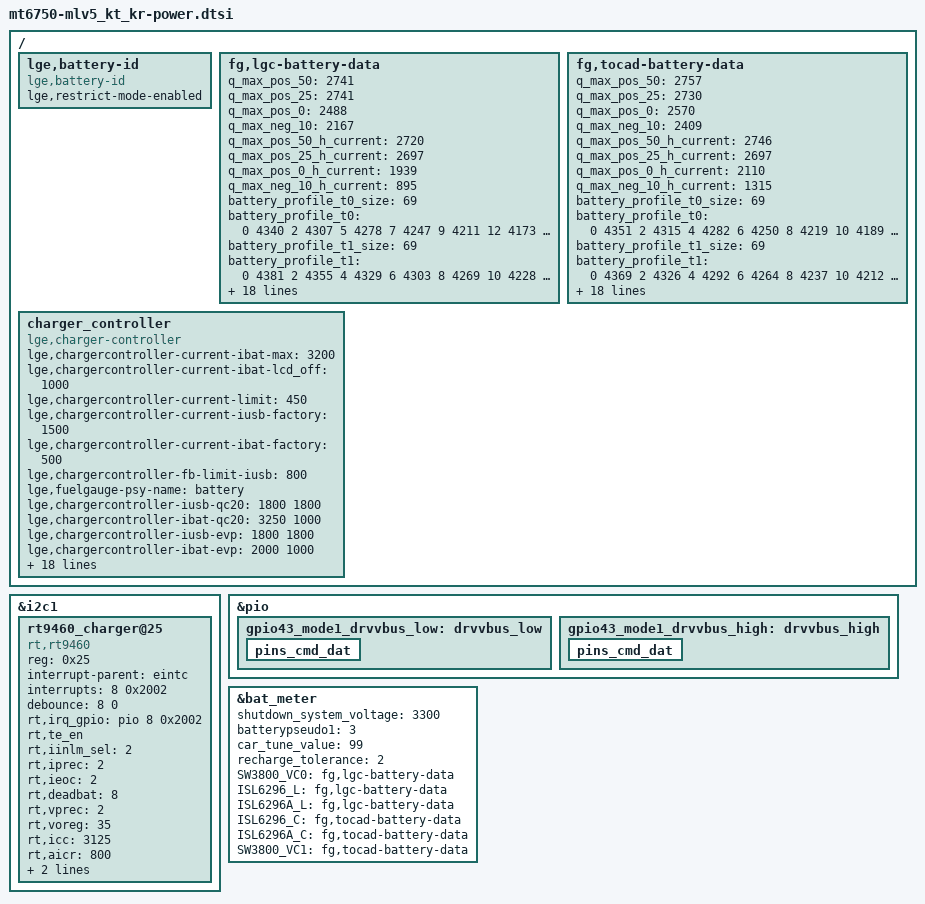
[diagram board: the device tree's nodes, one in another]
/*
 * LG Electronics LV5 power device tree source
 *
 * Copyright (c) 2016 LG Electronics Co., Ltd.
 *              http://www.lge.com
 *
 */

&i2c1 {
	rt9460_charger@25 {
		status = "okay";
		compatible = "rt,rt9460";
		reg = <0x25>;
		interrupt-parent = <&eintc>;
		interrupts = <8 0x2002>;
		debounce = <8 0>;
		rt,irq_gpio = <&pio 8 0x2002>;
		rt,te_en;
		rt,iinlm_sel = <2>;
		rt,iprec = <2>;
		rt,ieoc = <2>;
		rt,deadbat = <8>;
		rt,vprec = <2>;
		rt,voreg = <35>;
		rt,icc = <3125>;
		rt,aicr = <800>;
		rt,chg_volt = <4400>;
		rt,bst_volt = <5000>;
	};
};
/ {
	lge,battery-id{
		compatible = "lge,battery-id";
		lge,restrict-mode-enabled;
	};
};

&pio {
	gpio43_mode1_drvvbus_low: drvvbus_low{
		pins_cmd_dat {
			/delete-property/ pins;
			/delete-property/ slew-rate;
			/delete-property/ output-low;
		};
	};
	gpio43_mode1_drvvbus_high: drvvbus_high{
		pins_cmd_dat {
			/delete-property/ pins;
			/delete-property/ slew-rate;
			/delete-property/ output-high;
		};
	};
};

/* battery_profile */
&bat_meter {
	shutdown_system_voltage = <3300>;
	batterypseudo1 = <3 >;
	car_tune_value = <99 >;
	recharge_tolerance = <2>;
	/* battery id */ /*need to check for LGC 2nd battery and TOCAD battery ID*/
	SW3800_VC0 = "fg,lgc-battery-data";
	ISL6296_L = "fg,lgc-battery-data";
	ISL6296A_L = "fg,lgc-battery-data";
	ISL6296_C = "fg,tocad-battery-data";
	ISL6296A_C = "fg,tocad-battery-data";
	SW3800_VC1 = "fg,tocad-battery-data";
};

/{
	/* LGC 2800mA Battery 3.4V cut off */
	fg,lgc-battery-data {
		/* Qmax for 0mA */
		q_max_pos_50 = <2741 >;
		q_max_pos_25 = <2741 >;
		q_max_pos_0 = <2488 >;
		q_max_neg_10 = <2167 >;
		/* Qmax for 400mA, said high current */
		q_max_pos_50_h_current = <2720 >;
		q_max_pos_25_h_current = <2697 >;
		q_max_pos_0_h_current = <1939 >;
		q_max_neg_10_h_current = <895 >;

		battery_profile_t0_size = <69 >;
		battery_profile_t0 = <
			0 4340 	2 4307 	5 4278 	7 4247 	9 4211
			12 4173 	14 4143 	16 4118 	18 4097 	21 4076
			23 4051 	25 4024 	28 3997 	30 3974 	32 3953
			35 3935 	37 3919 	39 3903 	42 3887 	44 3873
			46 3862 	48 3850 	51 3839 	53 3829 	55 3820
			58 3811 	60 3803 	62 3795 	65 3789 	67 3782
			69 3776 	72 3768 	74 3760 	76 3752 	78 3743
			81 3733 	83 3723 	85 3713 	88 3701 	90 3688
			92 3671 	95 3643 	97 3589 	99 3473 	100 3353
			100 3272 	100 3219 	100 3175 	100 3136 	100 3101
			100 3078 	100 3061 	100 3045 	100 3027 	100 3007
			100 2997 	100 3001 	100 2999 	100 2995 	100 2992
			100 2989 	100 2515 	100 2517 	100 2520 	100 2515
			100 2521 	100 2519 	100 2520 	100 2520
			>;
		battery_profile_t1_size = <69 >;
		battery_profile_t1 = <
			0 4381 	2 4355 	4 4329 	6 4303 	8 4269
			10 4228 	12 4190 	14 4163 	16 4140 	18 4119
			20 4099 	22 4082 	24 4061 	26 4039 	28 4017
			30 3997 	32 3980 	34 3963 	36 3946 	38 3928
			40 3909 	42 3891 	44 3874 	46 3860 	48 3848
			50 3838 	52 3829 	54 3820 	56 3812 	58 3804
			60 3798 	62 3791 	64 3788 	66 3783 	68 3778
			70 3774 	72 3769 	74 3763 	76 3757 	78 3748
			80 3739 	82 3729 	84 3718 	86 3706 	88 3696
			90 3686 	92 3676 	94 3660 	96 3617 	98 3522
			100 3430 	100 3388 	100 3359 	100 3337 	100 3319
			100 3304 	100 3292 	100 3281 	100 3270 	100 3261
			100 3252 	100 3244 	100 3237 	100 3230 	100 3223
			100 3217 	100 3210 	100 3204 	100 3204
			>;
		battery_profile_t2_size = <69 >;
		battery_profile_t2 = <
			0 4389 	2 4356 	4 4329 	5 4304 	7 4280
			9 4258 	11 4236 	13 4214 	15 4193 	16 4171
			18 4151 	20 4131 	22 4111 	24 4092 	25 4074
			27 4057 	29 4038 	31 4018 	33 4001 	35 3986
			36 3972 	38 3959 	40 3944 	42 3929 	44 3914
			45 3894 	47 3875 	49 3859 	51 3847 	53 3836
			55 3828 	56 3819 	58 3813 	60 3805 	62 3799
			64 3794 	65 3788 	67 3783 	69 3779 	71 3775
			73 3771 	74 3766 	76 3761 	78 3752 	80 3744
			82 3737 	84 3727 	85 3714 	87 3700 	89 3685
			91 3680 	93 3676 	94 3669 	96 3639 	98 3552
			100 3411 	100 3104 	100 3035 	100 2997 	100 2971
			100 2956 	100 2947 	100 2941 	100 2934 	100 2929
			100 2927 	100 2926 	100 2921 	100 2921
			>;
		battery_profile_t3_size = <69 >;
		battery_profile_t3 = <
			0 4394 	2 4358 	4 4329 	5 4304 	7 4279
			9 4256 	11 4233 	13 4212 	15 4189 	16 4169
			18 4148 	20 4127 	22 4107 	24 4088 	25 4069
			27 4051 	29 4033 	31 4016 	33 3999 	35 3984
			36 3968 	38 3954 	40 3940 	42 3927 	44 3913
			45 3896 	47 3874 	49 3856 	51 3844 	53 3834
			55 3825 	56 3817 	58 3809 	60 3802 	62 3796
			64 3789 	65 3784 	67 3779 	69 3775 	71 3770
			73 3763 	74 3750 	76 3743 	78 3736 	80 3729
			82 3722 	84 3713 	85 3700 	87 3687 	89 3671
			91 3666 	93 3662 	94 3654 	96 3624 	98 3542
			100 3411 	100 3141 	100 2970 	100 2926 	100 2903
			100 2890 	100 2880 	100 2875 	100 2869 	100 2865
			100 2863 	100 2862 	100 2857 	100 2857
			>;
		r_profile_t0_size = <69 >;
		r_profile_t0 = <
			795 4340 	795 4307 	830 4278 	853 4247 	908 4211
			1018 4173 	1108 4143 	1145 4118 	1163 4097 	1210 4076
			1228 4051 	1223 4024 	1213 3997 	1208 3974 	1208 3953
			1205 3935 	1213 3919 	1215 3903 	1223 3887 	1228 3873
			1245 3862 	1250 3850 	1263 3839 	1268 3829 	1278 3820
			1283 3811 	1308 3803 	1320 3795 	1325 3789 	1360 3782
			1380 3776 	1415 3768 	1438 3760 	1458 3752 	1488 3743
			1528 3733 	1575 3723 	1613 3713 	1673 3701 	1740 3688
			1788 3671 	1835 3643 	1880 3589 	1493 3473 	1383 3353
			1183 3272 	1053 3219 	940 3175 	845 3136 	765 3101
			703 3078 	655 3061 	615 3045 	590 3027 	543 3007
			520 2997 	563 3001 	558 2999 	1350 2995 	978 2992
			1365 2989 	180 2515 	185 2517 	193 2520 	180 2515
			195 2521 	190 2519 	193 2520 	193 2520
			>;
		r_profile_t1_size = <69 >;
		r_profile_t1 = <
			345 4381 	345 4355 	353 4329 	363 4303 	378 4269
			423 4228 	513 4190 	568 4163 	585 4140 	590 4119
			595 4099 	620 4082 	643 4061 	648 4039 	645 4017
			643 3997 	648 3980 	653 3963 	653 3946 	658 3928
			653 3909 	653 3891 	650 3874 	648 3860 	655 3848
			663 3838 	673 3829 	678 3820 	688 3812 	695 3804
			705 3798 	715 3791 	730 3788 	743 3783 	768 3778
			785 3774 	805 3769 	828 3763 	855 3757 	880 3748
			913 3739 	948 3729 	988 3718 	1028 3706 	1078 3696
			1140 3686 	1218 3676 	1308 3660 	1398 3617 	1498 3522
			1578 3430 	1470 3388 	1400 3359 	1350 3337 	1303 3319
			1265 3304 	1233 3292 	1218 3281 	1183 3270 	1155 3261
			1138 3252 	1123 3244 	1095 3237 	1098 3230 	1070 3223
			1068 3217 	1055 3210 	1040 3204 	1020 3204
			>;
		r_profile_t2_size = <69 >;
		r_profile_t2 = <
			145 4389 	145 4356 	143 4329 	143 4304 	140 4280
			143 4258 	145 4236 	143 4214 	148 4193 	145 4171
			145 4151 	150 4131 	153 4111 	155 4092 	160 4074
			163 4057 	168 4038 	168 4018 	173 4001 	175 3986
			178 3972 	185 3959 	185 3944 	188 3929 	185 3914
			170 3894 	160 3875 	148 3859 	145 3847 	145 3836
			148 3828 	145 3819 	150 3813 	150 3805 	155 3799
			158 3794 	158 3788 	160 3783 	163 3779 	163 3775
			165 3771 	163 3766 	165 3761 	160 3752 	165 3744
			173 3737 	178 3727 	183 3714 	188 3700 	188 3685
			203 3680 	223 3676 	255 3669 	278 3639 	313 3552
			403 3411 	765 3104 	603 3035 	508 2997 	435 2971
			398 2956 	380 2947 	358 2941 	358 2934 	330 2929
			320 2927 	318 2926 	318 2921 	323 2921
			>;
		r_profile_t3_size = <69 >;
		r_profile_t3 = <
			98 4394 	98 4358 	98 4329 	98 4304 	95 4279
			95 4256 	95 4233 	98 4212 	95 4189 	100 4169
			100 4148 	100 4127 	100 4107 	103 4088 	105 4069
			108 4051 	108 4033 	110 4016 	110 3999 	115 3984
			115 3968 	120 3954 	123 3940 	128 3927 	130 3913
			128 3896 	113 3874 	103 3856 	100 3844 	100 3834
			100 3825 	103 3817 	103 3809 	105 3802 	108 3796
			110 3789 	113 3784 	115 3779 	118 3775 	120 3770
			115 3763 	103 3750 	105 3743 	105 3736 	108 3729
			110 3722 	110 3713 	110 3700 	110 3687 	108 3671
			113 3666 	120 3662 	128 3654 	125 3624 	140 3542
			163 3411 	280 3141 	425 2970 	315 2926 	270 2903
			235 2890 	213 2880 	198 2875 	183 2869 	170 2865
			165 2863 	160 2862 	160 2857 	145 2857
			>;
	};
	/* TOCAD 2800mA Battery 3.4V cut off */  /*temporary using lgc battery data*/
	fg,tocad-battery-data {
		/* Qmax for 0mA */
		q_max_pos_50 = <2757 >;
		q_max_pos_25 = <2730 >;
		q_max_pos_0 = <2570 >;
		q_max_neg_10 = <2409 >;
		/* Qmax for 400mA, said high current */
		q_max_pos_50_h_current = <2746 >;
		q_max_pos_25_h_current = <2697 >;
		q_max_pos_0_h_current = <2110 >;
		q_max_neg_10_h_current = <1315 >;

		battery_profile_t0_size = <69 >;
		battery_profile_t0 = <
			0 4351 	2 4315 	4 4282 	6 4250 	8 4219
			10 4189 	12 4162 	14 4138 	17 4113 	19 4090
			21 4068 	23 4047 	25 4026 	27 4004 	29 3985
			31 3967 	33 3948 	35 3930 	37 3910 	39 3891
			41 3874 	44 3858 	46 3845 	48 3833 	50 3822
			52 3813 	54 3807 	56 3801 	58 3797 	60 3792
			62 3789 	64 3785 	66 3782 	68 3778 	70 3773
			72 3769 	75 3762 	77 3755 	79 3746 	81 3734
			83 3723 	85 3711 	87 3700 	89 3691 	91 3682
			93 3673 	95 3659 	96 3649 	97 3645 	97 3640
			98 3636 	98 3633 	98 3629 	98 3625 	99 3621
			99 3616 	99 3612 	99 3608 	99 3603 	99 3599
			99 3594 	99 3590 	100 3585 	100 3581 	100 3577
			100 3573 	100 3569 	100 3564 	100 3400
			>;
		battery_profile_t1_size = <69 >;
		battery_profile_t1 = <
			0 4369 	2 4326 	4 4292 	6 4264 	8 4237
			10 4212 	12 4187 	14 4164 	16 4140 	17 4118
			19 4097 	21 4078 	23 4058 	25 4039 	27 4019
			29 4001 	31 3985 	33 3968 	35 3952 	37 3934
			39 3915 	41 3897 	43 3879 	45 3864 	47 3849
			49 3839 	50 3830 	52 3820 	54 3812 	56 3805
			58 3798 	60 3793 	62 3788 	64 3785 	66 3783
			68 3779 	70 3776 	72 3773 	74 3769 	76 3763
			78 3755 	80 3745 	81 3734 	83 3721 	85 3704
			87 3692 	89 3683 	91 3675 	93 3667 	95 3653
			97 3610 	98 3587 	98 3568 	98 3551 	99 3537
			99 3524 	99 3513 	99 3503 	99 3492 	99 3483
			99 3475 	100 3466 	100 3459 	100 3451 	100 3443
			100 3436 	100 3429 	100 3423 	100 3400
			>;
		battery_profile_t2_size = <69 >;
		battery_profile_t2 = <
			0 4386 	2 4357 	4 4335 	5 4314 	7 4292
			9 4271 	11 4250 	13 4228 	15 4207 	16 4186
			18 4165 	20 4144 	22 4124 	24 4104 	26 4085
			27 4067 	29 4048 	31 4030 	33 4014 	35 3997
			37 3982 	38 3968 	40 3953 	42 3936 	44 3917
			46 3896 	48 3878 	49 3864 	51 3852 	53 3842
			55 3833 	57 3825 	58 3817 	60 3811 	62 3804
			64 3798 	66 3793 	68 3788 	69 3783 	71 3779
			73 3775 	75 3770 	77 3765 	79 3758 	80 3750
			82 3742 	84 3729 	86 3716 	88 3697 	90 3688
			91 3686 	93 3683 	95 3678 	97 3642 	99 3538
			100 3348 	100 3141 	100 3064 	100 3030 	100 3010
			100 2997 	100 2989 	100 2979 	100 2972 	100 2965
			100 2960 	100 2957 	100 2952 	100 2952
			>;
		battery_profile_t3_size = <69 >;
		battery_profile_t3 = <
			0 4395 	2 4369 	4 4347 	5 4327 	7 4306
			9 4284 	11 4263 	13 4242 	14 4221 	16 4198
			18 4177 	20 4157 	22 4136 	24 4116 	25 4097
			27 4077 	29 4059 	31 4041 	33 4024 	34 4008
			36 3992 	38 3976 	40 3962 	42 3948 	43 3934
			45 3916 	47 3893 	49 3875 	51 3862 	52 3851
			54 3840 	56 3832 	58 3823 	60 3816 	62 3808
			63 3802 	65 3797 	67 3791 	69 3786 	71 3782
			72 3775 	74 3765 	76 3757 	78 3749 	80 3742
			81 3733 	83 3726 	85 3712 	87 3698 	89 3680
			90 3677 	92 3675 	94 3673 	96 3663 	98 3595
			99 3470 	100 3214 	100 3085 	100 3045 	100 3021
			100 3002 	100 2985 	100 2974 	100 2963 	100 2954
			100 2946 	100 2939 	100 2931 	100 2931
			>;
		r_profile_t0_size = <69 >;
		r_profile_t0 = <
			693 4351 	693 4315 	723 4282 	743 4250 	763 4219
			785 4189 	808 4162 	835 4138 	855 4113 	875 4090
			898 4068 	918 4047 	935 4026 	948 4004 	968 3985
			985 3967 	1000 3948 	1013 3930 	1015 3910 	1013 3891
			1008 3874 	1000 3858 	998 3845 	995 3833 	998 3822
			998 3813 	1010 3807 	1018 3801 	1030 3797 	1045 3792
			1068 3789 	1093 3785 	1123 3782 	1153 3778 	1183 3773
			1218 3769 	1245 3762 	1278 3755 	1315 3746 	1353 3734
			1400 3723 	1453 3711 	1518 3700 	1598 3691 	1700 3682
			1835 3673 	2035 3659 	2125 3649 	2115 3645 	2103 3640
			2093 3636 	2083 3633 	2078 3629 	2063 3625 	2060 3621
			2053 3616 	2035 3612 	2043 3608 	2023 3603 	2003 3599
			2005 3594 	2003 3590 	1970 3585 	1963 3581 	1958 3577
			1953 3573 	1948 3569 	1938 3564 	1520 3400
			>;
		r_profile_t1_size = <69 >;
		r_profile_t1 = <
			423 4369 	423 4326 	448 4292 	470 4264 	488 4237
			505 4212 	520 4187 	543 4164 	558 4140 	568 4118
			573 4097 	580 4078 	585 4058 	588 4039 	588 4019
			590 4001 	593 3985 	590 3968 	588 3952 	580 3934
			570 3915 	563 3897 	553 3879 	548 3864 	540 3849
			545 3839 	553 3830 	555 3820 	560 3812 	565 3805
			568 3798 	575 3793 	580 3788 	590 3785 	608 3783
			623 3779 	640 3776 	660 3773 	683 3769 	705 3763
			728 3755 	753 3745 	788 3734 	825 3721 	865 3704
			928 3692 	1015 3683 	1140 3675 	1333 3667 	1605 3653
			1988 3610 	1973 3587 	1928 3568 	1888 3551 	1863 3537
			1818 3524 	1795 3513 	1760 3503 	1740 3492 	1715 3483
			1710 3475 	1685 3466 	1685 3459 	1633 3451 	1658 3443
			1608 3436 	1625 3429 	1570 3423 	1528 3400
			>;
		r_profile_t2_size = <69 >;
		r_profile_t2 = <
			183 4386 	183 4357 	185 4335 	183 4314 	183 4292
			185 4271 	188 4250 	185 4228 	188 4207 	188 4186
			188 4165 	188 4144 	190 4124 	193 4104 	193 4085
			198 4067 	200 4048 	205 4030 	210 4014 	213 3997
			220 3982 	228 3968 	230 3953 	225 3936 	213 3917
			195 3896 	180 3878 	175 3864 	173 3852 	170 3842
			173 3833 	173 3825 	173 3817 	175 3811 	175 3804
			178 3798 	180 3793 	180 3788 	180 3783 	180 3779
			183 3775 	180 3770 	178 3765 	178 3758 	175 3750
			178 3742 	178 3729 	183 3716 	180 3697 	183 3688
			195 3686 	213 3683 	243 3678 	270 3642 	313 3538
			463 3348 	860 3141 	680 3064 	575 3030 	533 3010
			503 2997 	473 2989 	470 2979 	450 2972 	440 2965
			443 2960 	400 2957 	425 2952 	400 2952
			>;
		r_profile_t3_size = <69 >;
		r_profile_t3 = <
			100 4395 	100 4369 	98 4347 	100 4327 	103 4306
			100 4284 	103 4263 	103 4242 	105 4221 	103 4198
			103 4177 	108 4157 	105 4136 	108 4116 	110 4097
			110 4077 	113 4059 	115 4041 	115 4024 	120 4008
			123 3992 	125 3976 	135 3962 	140 3948 	148 3934
			143 3916 	123 3893 	110 3875 	105 3862 	103 3851
			100 3840 	103 3832 	105 3823 	108 3816 	105 3808
			108 3802 	110 3797 	113 3791 	115 3786 	120 3782
			115 3775 	108 3765 	103 3757 	103 3749 	103 3742
			100 3733 	103 3726 	100 3712 	103 3698 	98 3680
			100 3677 	103 3675 	113 3673 	115 3663 	118 3595
			135 3470 	233 3214 	715 3085 	628 3045 	555 3021
			520 3002 	493 2985 	453 2974 	425 2963 	403 2954
			390 2946 	350 2939 	358 2931 	368 2931
			>;
	};
};

/ {
	charger_controller: charger_controller {
		status = "ok";
		compatible = "lge,charger-controller";
		lge,chargercontroller-current-ibat-max = <3200>;
		lge,chargercontroller-current-ibat-lcd_off = <1000>;
		lge,chargercontroller-current-limit = <450>;
		lge,chargercontroller-current-iusb-factory = <1500>;
		lge,chargercontroller-current-ibat-factory = <500>;
		lge,chargercontroller-fb-limit-iusb = <800>;
		lge,fuelgauge-psy-name = "battery";
		lge,chargercontroller-iusb-qc20 = <1800 1800>;
		lge,chargercontroller-ibat-qc20 = <3250 1000>;
		lge,chargercontroller-iusb-evp = <1800 1800>;
		lge,chargercontroller-ibat-evp = <2000 1000>;
		/* lge,cable-adc-maxprop : size of each cable prop       */
		/* lge,cable-adc-lowthr : actual cable adc using set     */
		/* lge,cable-adc-channel : usb_id_lv or usb_id_lv_pu     */
		/* array : 0.TA, 1.USB, 2.set(200k_pu), 3.set(100k_pu)   */
		lge,cable-adc-maxprop  = <4>;
		lge,cable-adc-lowthr  = <2>;
		lge,cable-adc-channel  = <0x10>;
		lge,no-init-cable  = <   0    0       0       0>;
		lge,cable-mhl-1k   = < 500  500    5000   17500>;
		lge,cable-u-28p7k  = <1800  500  200000   19250>;
		lge,cable-28p7k    = <1800  500  300000   21000>;
		lge,cable-56k      = <1800 1500  490000  773000>;
		lge,cable-100k     = <1800  500  650000  958500>;
		lge,cable-130k     = <1800 1500  780000 1087000>;
		lge,cable-180k     = <1800  500  875000 1178500>;
		lge,cable-200k     = <1800  500  920000 1218500>;
		lge,cable-220k     = <1800  500  988000 1275000>;
		lge,cable-270k     = <1800  500 1077000 1347000>;
		lge,cable-330k     = <1800  500 1294000 1465500>;
		lge,cable-620k     = <1800  500 1418000 1585500>;
		lge,cable-910k     = <1800 1500 1600000 1710500>;
		lge,cable-none     = <1800  500 1900000 1900000>;
//		qcom,chg-vadc = <&auxadc>; /* edit point */
//		qcom,usb_id-vadc = <&auxadc>; /* edit point */
//		qcom,xo-vadc = <&therm_ctrl>; /* edit point */
	};
};
